VERSION "VehicleGPT project replay mapping; derived from verified OpenDBC Toyota RAV4 mapping"

NS_ :

BS_:

BU_: VehicleGPT

BO_ 37 STEER_ANGLE_SENSOR: 8 VehicleGPT
 SG_ STEER_ANGLE : 3|12@0- (1.5,0) [-3072|3070.5] "deg" VehicleGPT
 SG_ STEER_FRACTION : 39|4@0- (0.1,0) [-0.8|0.7] "deg" VehicleGPT

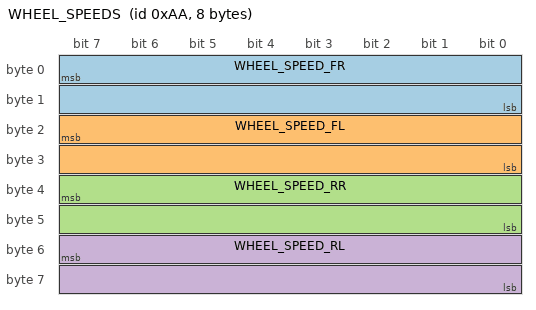
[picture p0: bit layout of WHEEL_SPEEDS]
BO_ 170 WHEEL_SPEEDS: 8 VehicleGPT
 SG_ WHEEL_SPEED_FR : 7|16@0+ (0.01,-67.67) [-67.67|587.68] "km/h" VehicleGPT
 SG_ WHEEL_SPEED_FL : 23|16@0+ (0.01,-67.67) [-67.67|587.68] "km/h" VehicleGPT
 SG_ WHEEL_SPEED_RR : 39|16@0+ (0.01,-67.67) [-67.67|587.68] "km/h" VehicleGPT
 SG_ WHEEL_SPEED_RL : 55|16@0+ (0.01,-67.67) [-67.67|587.68] "km/h" VehicleGPT

CM_ BO_ 37 "Project-local decode profile based on configs/comma2k19_dbc.yaml; segment validation in data/manifests/comma_dbc_validation.json. Not OEM-certified.";
CM_ BO_ 170 "Project-local decode profile based on configs/comma2k19_dbc.yaml; segment validation in data/manifests/comma_dbc_validation.json. Not OEM-certified.";
